# LPC5411x register map
Vendor: nxp.com; File version: 1.2
CPU: CM4 r0p1, little endian, MPU, FPU, VTOR, vendor SysTick, 3 interrupt priority bits
Registers are 32-bit, read-write, reset 0x0 unless marked. A register's access mark holds for its fields unless they carry their own. Offsets are from the block's base; [hi:lo] are bit positions; {n}, {i} and the like mark numbered series; 'fields as' and 'values as' point back to an identical list.

## IOCON — LPC5411x I/O pin configuration (IOCON)
Base 0x40001000
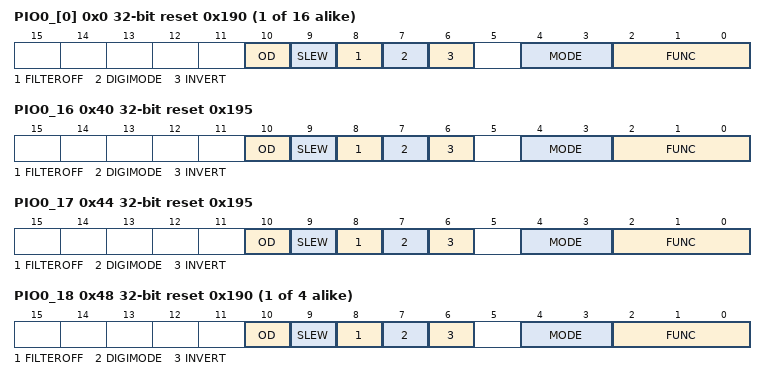
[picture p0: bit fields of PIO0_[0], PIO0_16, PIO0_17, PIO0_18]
{0x0+4i} PIO0_[{i}] (i=0..15) reset 0x190 — Digital I/O control for port 0 pins PIO0_0 to PIO0_15.
  [10] OD — Controls open-drain mode.
    0=NORMAL (Normal. Normal push-pull output); 1=OPEN_DRAIN (Open-drain. Simulated open-drain output (high drive disabled).)
  [9] SLEW — Driver slew rate.
    0=STANDARD (Standard mode, output slew rate control is enabled. More outputs can be switched simultaneously.); 1=FAST (Fast mode, slew rate control is disabled. Refer to the appropriate specific device data sheet for details.)
  [8] FILTEROFF — Controls input glitch filter.
    0=ENABLED (Filter enabled. Noise pulses below approximately 10 ns are filtered out.); 1=DISABLED (Filter disabled. No input filtering is done.)
  [7] DIGIMODE — Select Analog/Digital mode.
    0=ANALOG (Analog mode.); 1=DIGITAL (Digital mode.)
  [6] INVERT — Input polarity.
    0=DISABLED (Disabled. Input function is not inverted.); 1=ENABLED (Enabled. Input is function inverted.)
  [4:3] MODE — Selects function mode (on-chip pull-up/pull-down resistor control).
    0=INACTIVE (Inactive. Inactive (no pull-down/pull-up resistor enabled).); 1=PULL_DOWN (Pull-down. Pull-down resistor enabled.); 2=PULL_UP (Pull-up. Pull-up resistor enabled.); 3=REPEATER (Repeater. Repeater mode.)
  [2:0] FUNC — Selects pin function.
0x40 PIO0_16 reset 0x195 — Digital I/O control for port 0 pin PIO0_16.
  fields as PIO0_[0]
0x44 PIO0_17 reset 0x195 — Digital I/O control for port 0 pin PIO0_17.
  fields as PIO0_[0]
{0x0+4i} PIO0_{i} reset 0x190 (i=18..21) — Digital I/O control for port 0 pin PIO0_{i}
  fields as PIO0_[0]
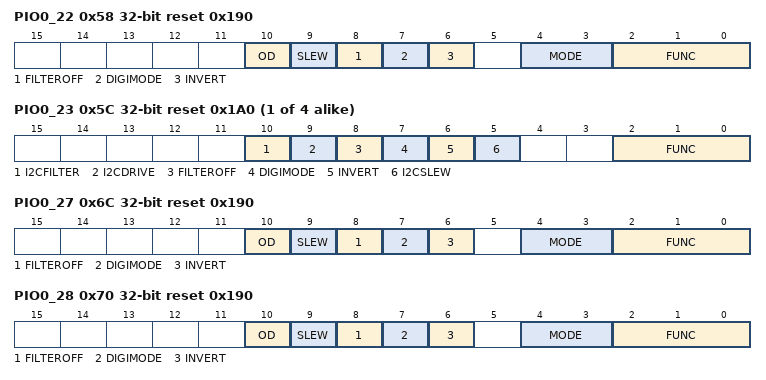
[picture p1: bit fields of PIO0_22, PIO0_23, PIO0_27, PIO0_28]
0x58 PIO0_22 reset 0x190 — Digital I/O control for port 0 pin PIO0_22.
  fields as PIO0_[0]
{0x0+4i} PIO0_{i} reset 0x1A0 (i=23..26) — Digital I/O control for port 0 pin PIO0_{i}. These pins support I 2C with true open-drain, drive and filtering for modes up to Fast-mode Plus.
  [10] I2CFILTER — Configures I2C features for standard mode, fast mode, and Fast Mode Plus operation.
    0=ENABLED (Enabled. I2C 50 ns glitch filter enabled.); 1=DISABLED (Disabled. I2C 50 ns glitch filter disabled.)
  [9] I2CDRIVE — Controls the current sink capability of the pin.
    0=LOW (Low drive. Output drive sink is 4 mA. This is sufficient for standard and fast mode I2C.); 1=HIGH (High drive. Output drive sink is 20 mA. This is needed for Fast Mode Plus I 2C. Refer to the appropriate specific device data sheet for details.)
  [8] FILTEROFF — Controls input glitch filter.
    values as PIO0_[0].FILTEROFF
  [7] DIGIMODE — Select Analog/Digital mode.
    0=ANALOG (Analog mode.); 1=DIGITAL (Digital mode.)
  [6] INVERT — Input polarity.
    values as PIO0_[0].INVERT
  [5] I2CSLEW — Controls slew rate of I2C pad.
    0=I2C_MODE; 1=GPIO_MODE
  [2:0] FUNC — Selects pin function.
0x6C PIO0_27 reset 0x190 — Digital I/O control for port 0 pins PIO0_27.
  fields as PIO0_[0]
0x70 PIO0_28 reset 0x190 — Digital I/O control for port 0 pin PIO0_28.
  fields as PIO0_[0]
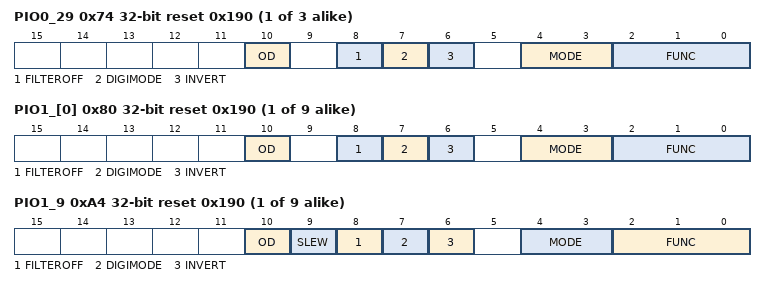
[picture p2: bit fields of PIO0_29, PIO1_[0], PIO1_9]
{0x0+4i} PIO0_{i} reset 0x190 (i=29..31) — Digital I/O control for port 0 pins PIO0_{i}. These pins include an ADC input.
  [10] OD — Controls open-drain mode.
    values as PIO0_[0].OD
  [8] FILTEROFF — Controls input glitch filter.
    values as PIO0_[0].FILTEROFF
  [7] DIGIMODE — Select Analog/Digital mode.
    0=ANALOG (Analog mode.); 1=DIGITAL (Digital mode.)
  [6] INVERT — Input polarity.
    values as PIO0_[0].INVERT
  [4:3] MODE — Selects function mode (on-chip pull-up/pull-down resistor control).
    values as PIO0_[0].MODE
  [2:0] FUNC — Selects pin function.
{0x80+4i} PIO1_[{i}] (i=0..8) reset 0x190 — Digital I/O control for port 1 pins PIO0_0 to PIO0_8. These pins include an ADC input.
  fields as PIO0_29
{0x80+4i} PIO1_{i} reset 0x190 (i=9..17) — Digital I/O control for port 1 pins PIO1_{i}.
  fields as PIO0_[0]
